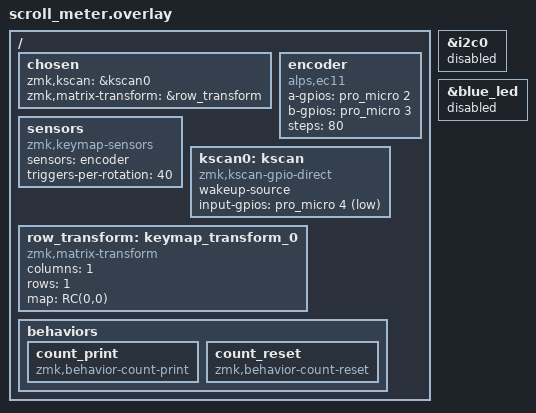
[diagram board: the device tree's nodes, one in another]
#include <dt-bindings/zmk/matrix_transform.h>

/ {
    chosen {
        zmk,kscan = &kscan0;
        zmk,matrix-transform = &row_transform;
    };

    /* Final wiring:
         A      → D2 (P0.17)   - encoder rotation phase A
         B      → D3 (P0.20)   - encoder rotation phase B
         C      → GND          - encoder common
         Switch → D4 (P0.22) → GND when pressed */
    encoder: encoder {
        compatible = "alps,ec11";
        a-gpios = <&pro_micro 2 (GPIO_ACTIVE_HIGH | GPIO_PULL_UP)>;
        b-gpios = <&pro_micro 3 (GPIO_ACTIVE_HIGH | GPIO_PULL_UP)>;
        steps = <80>;
        status = "okay";
    };

    sensors: sensors {
        compatible = "zmk,keymap-sensors";
        sensors = <&encoder>;
        triggers-per-rotation = <40>;
    };

    kscan0: kscan {
        compatible = "zmk,kscan-gpio-direct";
        wakeup-source;
        input-gpios = <&pro_micro 4 (GPIO_ACTIVE_LOW | GPIO_PULL_UP)>;
    };

    row_transform: keymap_transform_0 {
        compatible = "zmk,matrix-transform";
        columns = <1>;
        rows = <1>;
        map = <RC(0,0)>;
    };

    behaviors {
        count_print: count_print {
            compatible = "zmk,behavior-count-print";
            #binding-cells = <0>;
        };
        count_reset: count_reset {
            compatible = "zmk,behavior-count-reset";
            #binding-cells = <0>;
        };
    };
};

&i2c0  { status = "disabled"; };

&blue_led {
    status = "disabled";
};
